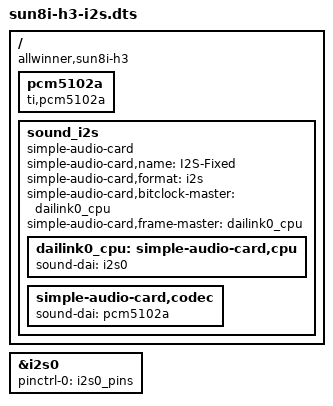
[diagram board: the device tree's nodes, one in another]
/dts-v1/;
/plugin/;

/ {
    compatible = "allwinner,sun8i-h3";

    fragment@0 {
        target = <&i2s0>;
        __overlay__ {
            status = "okay";
            pinctrl-0 = <&i2s0_pins>;
            pinctrl-names = "default";
            #sound-dai-cells = <0>;
        };
    };

    fragment@1 {
        target-path = "/";
        __overlay__ {
            pcm5102a: pcm5102a {
                #sound-dai-cells = <0>;
                compatible = "ti,pcm5102a";
                status = "okay";
            };

            sound_i2s {
                compatible = "simple-audio-card";
                simple-audio-card,name = "I2S-Fixed";
                simple-audio-card,format = "i2s";
                
                /* FORCE ORANGE PI AS MASTER */
                simple-audio-card,bitclock-master = <&dailink0_cpu>;
                simple-audio-card,frame-master = <&dailink0_cpu>;

                dailink0_cpu: simple-audio-card,cpu {
                    sound-dai = <&i2s0>;
                };

                simple-audio-card,codec {
                    sound-dai = <&pcm5102a>;
                };
            };
        };
    };
};
